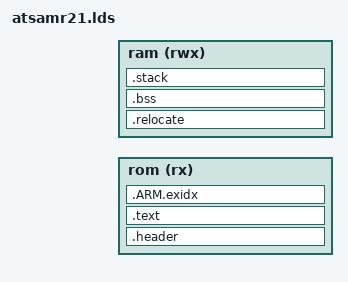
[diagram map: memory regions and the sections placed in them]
/**
 * \file
 *
 * \brief Linker script for running in internal FLASH on the SAMR21G18A
 *
 * Copyright (c) 2014 Atmel Corporation. All rights reserved.
 *
 * \asf_license_start
 *
 * \page License
 *
 * Redistribution and use in source and binary forms, with or without
 * modification, are permitted provided that the following conditions are met:
 *
 * 1. Redistributions of source code must retain the above copyright notice,
 *    this list of conditions and the following disclaimer.
 *
 * 2. Redistributions in binary form must reproduce the above copyright notice,
 *    this list of conditions and the following disclaimer in the documentation
 *    and/or other materials provided with the distribution.
 *
 * 3. The name of Atmel may not be used to endorse or promote products derived
 *    from this software without specific prior written permission.
 *
 * 4. This software may only be redistributed and used in connection with an
 *    Atmel microcontroller product.
 *
 * THIS SOFTWARE IS PROVIDED BY ATMEL "AS IS" AND ANY EXPRESS OR IMPLIED
 * WARRANTIES, INCLUDING, BUT NOT LIMITED TO, THE IMPLIED WARRANTIES OF
 * MERCHANTABILITY, FITNESS FOR A PARTICULAR PURPOSE AND NON-INFRINGEMENT ARE
 * EXPRESSLY AND SPECIFICALLY DISCLAIMED. IN NO EVENT SHALL ATMEL BE LIABLE FOR
 * ANY DIRECT, INDIRECT, INCIDENTAL, SPECIAL, EXEMPLARY, OR CONSEQUENTIAL
 * DAMAGES (INCLUDING, BUT NOT LIMITED TO, PROCUREMENT OF SUBSTITUTE GOODS
 * OR SERVICES; LOSS OF USE, DATA, OR PROFITS; OR BUSINESS INTERRUPTION)
 * HOWEVER CAUSED AND ON ANY THEORY OF LIABILITY, WHETHER IN CONTRACT,
 * STRICT LIABILITY, OR TORT (INCLUDING NEGLIGENCE OR OTHERWISE) ARISING IN
 * ANY WAY OUT OF THE USE OF THIS SOFTWARE, EVEN IF ADVISED OF THE
 * POSSIBILITY OF SUCH DAMAGE.
 *
 * \asf_license_stop
 *
 */


OUTPUT_FORMAT("elf32-littlearm", "elf32-littlearm", "elf32-littlearm")
OUTPUT_ARCH(arm)
SEARCH_DIR(.)

/* Memory Spaces Definitions */
MEMORY
{
  rom (rx)  : ORIGIN = FLASH_START_ADDRESS, LENGTH = FLASH_SIZE
  ram (rwx) : ORIGIN = SRAM_START_ADDRESS, LENGTH = SRAM_SIZE
}
ENTRY(Reset_Handler)

/* The stack size used by the application. NOTE: you need to adjust according to your application. */
STACK_SIZE = DEFINED(STACK_SIZE) ? STACK_SIZE : DEFINED(__stack_size__) ? __stack_size__ : 0x2800;

/* Section Definitions */
SECTIONS
{
    .header : {
        . = ALIGN(4);
        _sfixed = .;
        KEEP(*(.vectors .vectors.*))
        . = ALIGN(4);

        _header = .;

        /* This is the binary header.
         * It starts with a signature: *EasyRF*
         */
        BYTE(0x2A)
        BYTE(0x45)
        BYTE(0x61)
        BYTE(0x73)
        BYTE(0x79)
        BYTE(0x52)
        BYTE(0x46)
        BYTE(0x2A)

        /* Next up is the version, which we take from the TIME
        variable, which is set during the CPP pre-processing of this
        file. */
        LONG(TIME)

        /* Then we have the header pointer, which should protect
        against booting this firmware from the wrong location in
        memory. We have defined _header = .; above, so we can use it
        here. */
        LONG(_header)

        /* The _sfixed pointer points to the first byte of the vector
        table. This is used by the loader to know where to start the
        loaded firmware. */
        LONG(_sfixed)

        /* Finally, we have a pointer to the byte after the last byte
        in the file. We compute this as the address of the .text
        segment plus the length of the .text and .data segments. */
        LONG(_efixed)
    } > rom

    .text :
    {
        . = ALIGN(4);
        *(.text .text.* .gnu.linkonce.t.*)
        *(.glue_7t) *(.glue_7)
        *(.rodata .rodata* .gnu.linkonce.r.*)
        *(.ARM.extab* .gnu.linkonce.armextab.*)

        /* Support C constructors, and C destructors in both user code
           and the C library. This also provides support for C++ code. */
        . = ALIGN(4);
        KEEP (*(.init))
        . = ALIGN(4);
        __preinit_array_start = .;
        KEEP (*(.preinit_array))
        __preinit_array_end = .;

        . = ALIGN(4);
        __init_array_start = .;
        KEEP (*(SORT(.init_array.*)))
        KEEP (*(.init_array))
        __init_array_end = .;

        . = ALIGN(4);
        KEEP (*crtbegin.o(.ctors))
        KEEP (*(EXCLUDE_FILE (*crtend.o) .ctors))
        KEEP (*(SORT(.ctors.*)))
        KEEP (*crtend.o(.ctors))

        . = ALIGN(4);
        KEEP(*(.fini))

        . = ALIGN(4);
        __fini_array_start = .;
        KEEP (*(.fini_array))
        KEEP (*(SORT(.fini_array.*)))
        __fini_array_end = .;

        KEEP (*crtbegin.o(.dtors))
        KEEP (*(EXCLUDE_FILE (*crtend.o) .dtors))
        KEEP (*(SORT(.dtors.*)))
        KEEP (*crtend.o(.dtors))

        . = ALIGN(4);
        _efixed = .;            /* End of text section */
    } > rom

    /* .ARM.exidx is sorted, so has to go in its own output section.  */
    PROVIDE_HIDDEN (__exidx_start = .);
    .ARM.exidx :
    {
      *(.ARM.exidx* .gnu.linkonce.armexidx.*)
    } > rom
    PROVIDE_HIDDEN (__exidx_end = .);

    . = ALIGN(4);
    _etext = .;

    .relocate : AT (_etext)
    {
        . = ALIGN(4);
        _srelocate = .;
        *(.ramfunc .ramfunc.*);
        *(.data .data.*);
        . = ALIGN(4);
        _erelocate = .;
    } > ram

    /* .bss section which is used for uninitialized data */
    .bss (NOLOAD) :
    {
        . = ALIGN(4);
        _sbss = . ;
        _szero = .;
        *(.bss .bss.*)
        *(COMMON)
        . = ALIGN(4);
        _ebss = . ;
        _ezero = .;
    } > ram

    /* stack section */
    .stack (NOLOAD):
    {
        . = ALIGN(8);
        _sstack = .;
        . = . + STACK_SIZE;
        . = ALIGN(8);
        _estack = .;
    } > ram

    . = ALIGN(4);
    _end = . ;
}
